# STM32N655 register map
File version: 1.0
CPU: CM55 r0p1, little endian, no MPU, FPU, vendor SysTick, 8 interrupt priority bits
Registers are 32-bit, read-write, reset 0x0 unless marked. A register's access mark holds for its fields unless they carry their own. Offsets are from the block's base; [hi:lo] are bit positions; 'fields as' and 'values as' point back to an identical list.

## LTDC — LCD-TFT display controller
Base 0x48001000
Same registers: LTDC_S 0x58001000
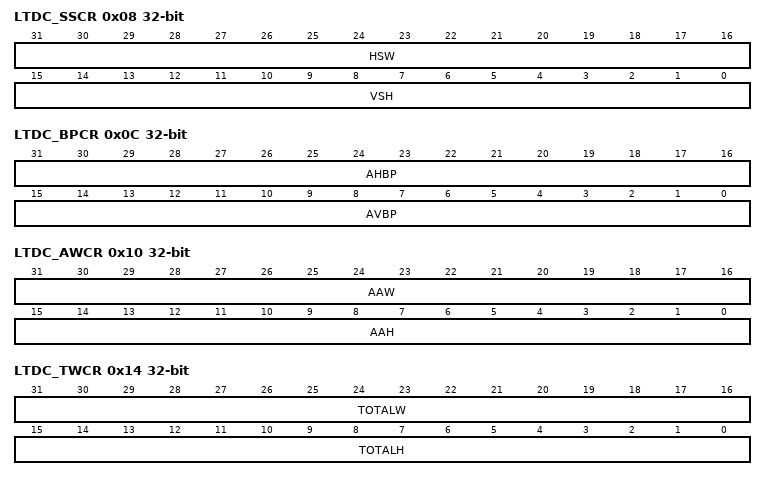
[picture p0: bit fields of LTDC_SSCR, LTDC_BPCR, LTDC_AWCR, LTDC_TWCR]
0x08 LTDC_SSCR — LTDC synchronization size configuration register
  [31:16] HSW — horizontal synchronization width (in units of pixel clock period)
  [15:0] VSH — vertical synchronization height (in units of horizontal scan line)
0x0C LTDC_BPCR — LTDC back porch configuration register
  [31:16] AHBP — accumulated horizontal back porch (in units of pixel clock period)
  [15:0] AVBP — accumulated Vertical back porch (in units of horizontal scan line)
0x10 LTDC_AWCR — LTDC active width configuration register
  [31:16] AAW — accumulated active width (in units of pixel clock period)
  [15:0] AAH — accumulated active height (in units of horizontal scan line)
0x14 LTDC_TWCR — LTDC total width configuration register
  [31:16] TOTALW — total width (in units of pixel clock period)
  [15:0] TOTALH — total height (in units of horizontal scan line)
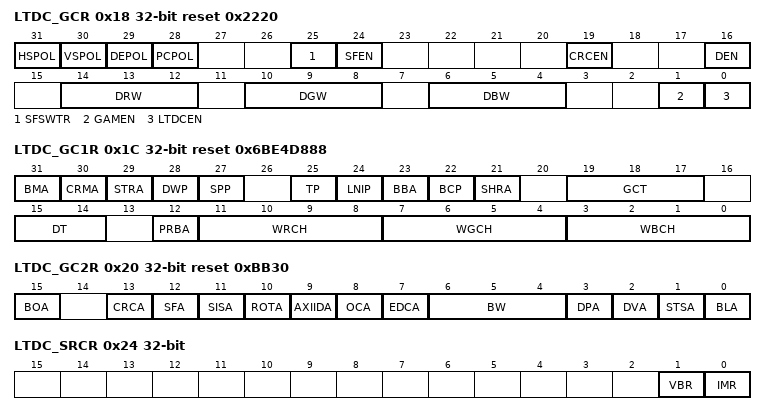
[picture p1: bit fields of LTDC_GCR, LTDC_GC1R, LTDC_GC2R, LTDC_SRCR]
0x18 LTDC_GCR access per field reset 0x2220 — LTDC global control register
  [31] HSPOL rw — horizontal synchronization polarity
    0=horizontal synchronization polarity is active low; 1=horizontal synchronization polarity is active high
  [30] VSPOL rw — vertical synchronization polarity
    0=vertical synchronization is active low; 1=vertical synchronization is active high
  [29] DEPOL rw — blanking (no data/pixel) polarity
    0=blanking (no data/pixel) polarity is active low; 1=blanking (no data/pixel) polarity is active high
  [28] PCPOL rw — pixel clock polarity
    0=the pixel and sync data are generated at the rising-edge of the output LCD_CLK clock; 1=the pixel and sync data are generated at the falling-edge of the output LCD_CLK clock
  [25] SFSWTR wo — single-frame mode: software trigger
    0=no action; 1=triggers one frame
  [24] SFEN rw — single-frame mode: mode enable
    0=single-frame disabled: a trigger (on SFSWTR) generates a continuous flow; 1=single-frame enabled: a trigger (on SFSWTR) generates a single frame
  [19] CRCEN rw — CRC enable
    0=CRC disabled; 1=CRC enabled
  [16] DEN rw — dither enable
    0=dither disabled; 1=dither enabled
  [14:12] DRW ro — dither red width
  [10:8] DGW ro — dither green width
  [6:4] DBW ro — dither blue width
  [1] GAMEN rw — Gamma correction enable
    0=Gamma correction disabled (pixels bypass the gamma operator); 1=Gamma correction enabled
  [0] LTDCEN rw — LTDC global enable
    0=LTDC disabled; 1=LTDC enabled
0x1C LTDC_GC1R ro reset 0x6BE4D888 — LTDC global configuration 1 register
  [31] BMA — blind mode ability
  [30] CRMA — configuration reading mode ability
  [29] STRA — status register ability
  [28] DWP — dither width programmability
  [27] SPP — sync polarity programmability
  [25] TP — timing programmability
  [24] LNIP — line-IRQ: line position programmability
  [23] BBA — background blending ability
  [22] BCP — background color programmability (unique color blended as background)
  [21] SHRA — shadow registers ability
  [19:17] GCT — gamma correction technique implemented
    0=no gamma; 1=gamma with 256 samples; 2=gamma with 8 interpolated segments
  [15:14] DT — dithering technique implemented
    0=no dithering; 1=ordered 4x4 Bayer; 3=pseudo-random LFSR
  [12] PRBA — precise blending ability
  [11:8] WRCH — width of red channel output
  [7:4] WGCH — width of green channel output
  [3:0] WBCH — width of blue channel output
0x20 LTDC_GC2R ro reset 0xBB30 — LTDC global configuration 2 register
  [15] BOA — blending order ability
    0=blending order fixed; 1=blending order configurable
  [13] CRCA — CRC ability
    0=CRC no computation available; 1=CRC computation available
  [12] SFA — single frame mode ability
    0=single frame not available; 1=single frame available
  [11] SISA — second interrupt set ability
    0=second interrupt set not available; 1=second interrupt set available
  [10] ROTA — rotation support ability
  [9] AXIIDA — AXIID ability
  [8] OCA — output conversion ability (RGB to YCbCr)
  [7] EDCA — external display control ability
  [6:4] BW — bus width (log2 of number of bytes)
    2=32-bit bus; 3=64-bit bus; 4=128-bit bus
  [3] DPA — secondary RGB output port ability
  [2] DVA — dual-view ability
  [1] STSA — slave timings synchronization ability
  [0] BLA — background layer ability (pixels of background layer are read from memory)
0x24 LTDC_SRCR — LTDC shadow reload configuration register
  [1] VBR — vertical blanking reload request
    0=no effect; 1=The shadow registers are reloaded during the vertical blanking period (at the beginning of the first line after the active display area)
  [0] IMR — immediate reload trigger
    0=no effect; 1=The shadow registers are reloaded immediately
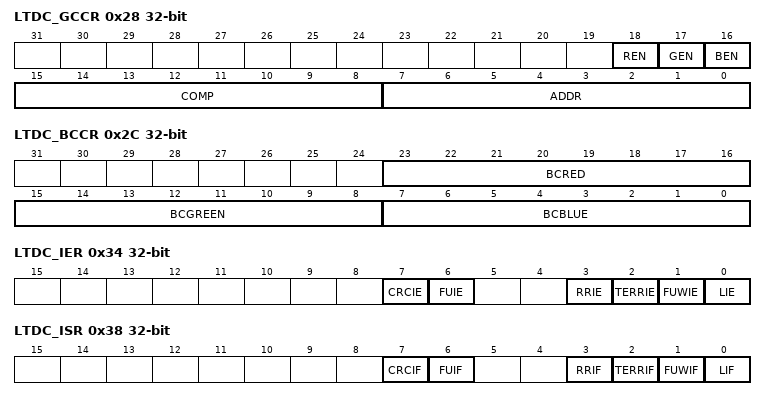
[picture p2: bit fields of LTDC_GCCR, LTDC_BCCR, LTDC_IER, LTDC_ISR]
0x28 LTDC_GCCR wo — LTDC gamma correction configuration register
  [18] REN — write trigger to the red table
    0=no action done; 1=COMP is written at ADDR in the red table
  [17] GEN — write trigger to the green table
    0=no action done; 1=COMP is written at ADDR in the green table
  [16] BEN — write trigger to the blue table
    0=no action done; 1=COMP is written at ADDR in the blue table
  [15:8] COMP — color component to be written, in either (or all) the R,G,B tables
  [7:0] ADDR — address of the R,G,B table where the COMP component is written
0x2C LTDC_BCCR — LTDC background color configuration register
  [23:16] BCRED — background color red value
  [15:8] BCGREEN — background color green value
  [7:0] BCBLUE — background color blue value
0x34 LTDC_IER — LTDC interrupt enable register
  [7] CRCIE — CRC error interrupt enable
    0=CRC error disabled; 1=CRC error interrupt enabled
  [6] FUIE — FIFO underrun interrupt enable
    0=FIFO underrun interrupt disabled; 1=FIFO underrun Interrupt enabled
  [3] RRIE — Register reload interrupt enable
    0=register reload interrupt disabled; 1=register reload interrupt enabled
  [2] TERRIE — Transfer Error interrupt enable
    0=transfer error interrupt disabled; 1=transfer error interrupt enabled
  [1] FUWIE — FIFO underrun warning interrupt enable
    values as FUIE
  [0] LIE — Line interrupt enable
    0=line interrupt disabled; 1=line interrupt enabled
0x38 LTDC_ISR ro — LTDC interrupt status register
  [7] CRCIF — CRC error interrupt flag
    0=no CRC error interrupt generated; 1=CRC error interrupt generated when a bus error occurs
  [6] FUIF — FIFO underrun interrupt flag
    0=no FIFO underrun interrupt generated; 1=FIFO underrun interrupt generated, if one of the layer FIFOs is empty and many pixel data are read from the FIFO
  [3] RRIF — Register reload interrupt flag
    0=no register reload interrupt generated; 1=register reload interrupt generated when a vertical blanking reload occurs (and the first line after the active area is reached)
  [2] TERRIF — Transfer error interrupt flag
    0=no transfer error interrupt generated; 1=transfer error interrupt generated when a bus error occurs
  [1] FUWIF — FIFO underrun warning interrupt flag
    0=no FIFO underrun warning interrupt generated; 1=FIFO underrun warning interrupt generated, if one of the layer FIFO is empty and pixel data is read from the FIFO
  [0] LIF — Line interrupt flag
    0=no line interrupt generated; 1=line interrupt generated when a programmed line is reached
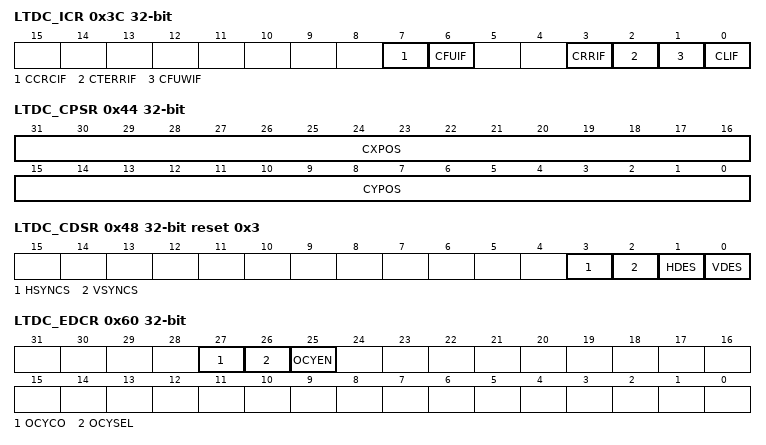
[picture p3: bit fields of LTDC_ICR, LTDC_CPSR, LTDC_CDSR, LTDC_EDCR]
0x3C LTDC_ICR wo — LTDC interrupt clear register
  [7] CCRCIF — clears the CRC error interrupt flag
    0=no effect; 1=clears the CRCIF flag in LTDC_ISR
  [6] CFUIF — clears the FIFO underrun interrupt flag
    0=no effect; 1=clears the FUIF flag in LTDC_ISR
  [3] CRRIF — clears register reload interrupt flag
    0=no effect; 1=clears the RRIF flag in LTDC_ISR
  [2] CTERRIF — clears the transfer error interrupt flag
    0=no effect; 1=clears the TERRIF flag in LTDC_ISR
  [1] CFUWIF — clears the FIFO underrun warning interrupt flag
    0=no effect; 1=clears the FUWIF flag in LTDC_ISR
  [0] CLIF — clears the line interrupt flag
    0=no effect; 1=clears the LIF flag in LTDC_ISR
0x40 LTDC_LIPCR — LTDC line interrupt position configuration register
  [15:0] LIPOS — line interrupt position
0x44 LTDC_CPSR ro — LTDC current position status register
  [31:16] CXPOS — current X position
  [15:0] CYPOS — current Y position
0x48 LTDC_CDSR ro reset 0x3 — LTDC current display status register
  [all] fields
    0=active low; 1=active high
  [3] HSYNCS — horizontal synchronization display status
  [2] VSYNCS — vertical synchronization display status
  [1] HDES — horizontal data enable display status
  [0] VDES — vertical data enable display status
0x60 LTDC_EDCR — LTDC external display control register
  [27] OCYCO — output conversion to YCbCr 422
    0=Cb is output first (Y0Cb, then Y1Cr, Y2Cb and so on); 1=Cr is output first (Y0Cr, then Y1Cb, Y2Cr and so on)
  [26] OCYSEL — output conversion to YCbCr 422
    0=use ITU-R BT.601 set (for typically SDTV analog-like displays); 1=use ITU-R BT.709 set (for typically HDTV digital-like displays)
  [25] OCYEN — output conversion to YCbCr 422 enable
    0=conversion disabled; 1=conversion enabled
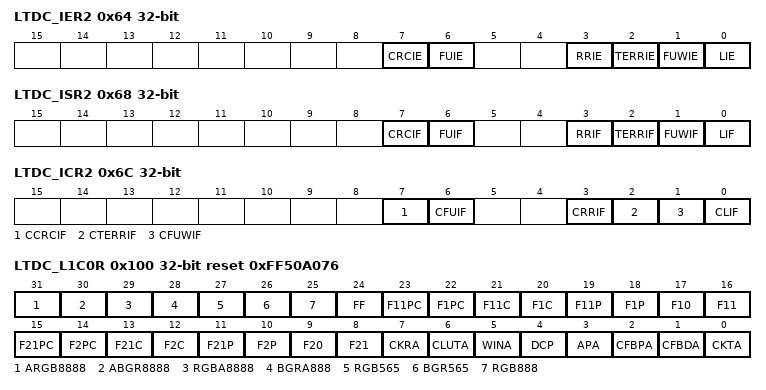
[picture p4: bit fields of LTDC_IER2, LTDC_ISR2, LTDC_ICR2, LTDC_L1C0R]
0x64 LTDC_IER2 — LTDC interrupt enable register 2
  [7] CRCIE — CRC error interrupt enable
    0=CRC error disabled; 1=CRC error interrupt enabled
  [6] FUIE — FIFO underrun interrupt enable
    values as LTDC_IER.FUIE
  [3] RRIE — Register reload interrupt enable
    values as LTDC_IER.RRIE
  [2] TERRIE — Transfer error interrupt enable
    values as LTDC_IER.TERRIE
  [1] FUWIE — FIFO underrun warning interrupt enable
    values as LTDC_IER.FUIE
  [0] LIE — Line interrupt enable
    0=line interrupt disabled; 1=line interrupt enabled
0x68 LTDC_ISR2 ro — LTDC interrupt status register 2
  [7] CRCIF — CRC Error interrupt flag
    values as LTDC_ISR.CRCIF
  [6] FUIF — FIFO underrun interrupt flag
    0=no FIFO underrun interrupt generated; 1=FIFO underrun interrupt generated, if one of the layer FIFO is empty and many pixel data are read from the FIFO
  [3] RRIF — Register reload interrupt flag
    values as LTDC_ISR.RRIF
  [2] TERRIF — Transfer error interrupt flag
    values as LTDC_ISR.TERRIF
  [1] FUWIF — FIFO underrun warning interrupt flag
    values as LTDC_ISR.FUWIF
  [0] LIF — Line interrupt flag
    values as LTDC_ISR.LIF
0x6C LTDC_ICR2 wo — LTDC interrupt clear register 2
  [7] CCRCIF — clears the CRC error interrupt flag
    0=no effect; 1=clears the CRCIF flag in LTDC_ISR2
  [6] CFUIF — clears the FIFO underrun interrupt flag
    0=no effect; 1=clears the FUIF flag in LTDC_ISR2
  [3] CRRIF — clears register reload interrupt flag
    0=no effect; 1=clears the RRIF flag in LTDC_ISR2
  [2] CTERRIF — clears the Transfer Error interrupt flag
    0=no effect; 1=clears the TERRIF flag in LTDC_ISR2
  [1] CFUWIF — clears the FIFO underrun warning interrupt flag
    0=no effect; 1=clears the FUWIF flag in LTDC_ISR2
  [0] CLIF — clears the Line interrupt flag
    0=no effect; 1=clears the LIF flag in LTDC_ISR2
0x70 LTDC_LIPCR2 — LTDC line interrupt position configuration register 2
  [15:0] LIPOS — line interrupt position
0x78 LTDC_ECRCR — LTDC expected CRC register
  [15:0] ECRC — expected CRC of frame
0x7C LTDC_CCRCR ro — LTDC computed CRC register
  [15:0] CCRC — computed CRC of frame
0x90 LTDC_FUTR reset 0x10 — LTDC FIFO underrun threshold register
  [15:0] THRE — threshold to trigger a FIFO underrun interrupt (per FIFO word, 64 bits)
0x100 LTDC_L1C0R ro reset 0xFF50A076 — LTDC layerx configuration 0 register
  [31] ARGB8888 — pixel format, ability for argb8888
  [30] ABGR8888 — pixel format, ability for abgr8888
  [29] RGBA8888 — pixel format, ability for rgba8888
  [28] BGRA888 — pixel format, ability for bgra8888
  [27] RGB565 — pixel format, ability for rgb565
  [26] BGR565 — pixel format, ability for bgr565
  [25] RGB888 — pixel format, ability for rgb888
  [24] FF — flexible pixel format, ability
  [23] F11PC — blending factor 1, ability for: 1.0 - (pixel_alpha * constant_alpha)
  [22] F1PC — blending factor 1, ability for: pixel_alpha * constant_alpha
  [21] F11C — blending factor 1, ability for: 1.0 - constant_alpha
  [20] F1C — blending factor 1, ability for: constant_alpha
  [19] F11P — blending factor 1, ability for: 1.0 - pixel_alpha
  [18] F1P — blending factor 1, ability for: pixel_alpha
  [17] F10 — blending factor 1,ability for: 0.0
  [16] F11 — blending factor 1, ability for: 1.0
  [15] F21PC — blending factor 2, ability for: 1.0 - (pixel_alpha * constant_alpha)
  [14] F2PC — blending factor 2, ability for: pixel_alpha * constant_alpha
  [13] F21C — blending factor 2, ability for: 1.0 - constant_alpha
  [12] F2C — blending factor 2, ability for: constant_alpha
  [11] F21P — blending factor 2, ability for: 1.0 - pixel_alpha
  [10] F2P — blending factor 2, ability for: pixel_alpha
  [9] F20 — blending factor 2, ability for: 0.0
  [8] F21 — blending factor 2, ability for: 1.0
  [7] CKRA — color key replace ability
  [6] CLUTA — CLUT ability
  [5] WINA — windowing ability
  [4] DCP — default color programmability
  [3] APA — alpha plane ability
  [2] CFBPA — color frame buffer pitch ability
  [1] CFBDA — color frame buffer duplication ability
  [0] CKTA — color key transparency ability
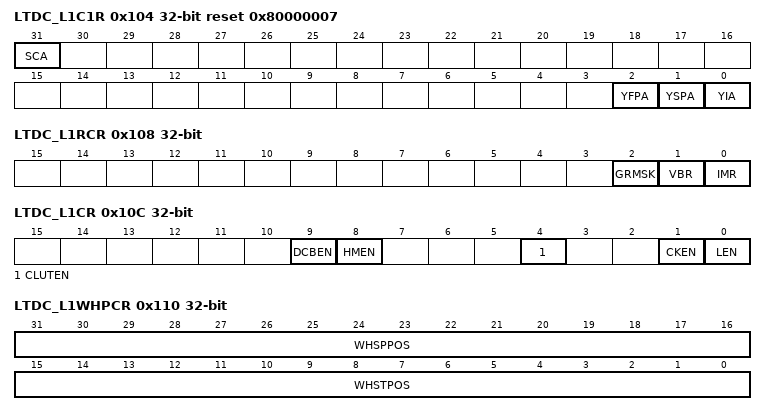
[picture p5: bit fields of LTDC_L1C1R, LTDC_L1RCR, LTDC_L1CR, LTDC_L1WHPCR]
0x104 LTDC_L1C1R access per field reset 0x80000007 — LTDC layerx configuration 1 register
  [31] SCA rw — scaling ability for that layer
    0=scaling not available; 1=scaling available
  [2] YFPA rw — YCbCr 420 full-planar ability for that layer
    0=full planar not available; 1=full planar available
  [1] YSPA rw — YCbCr 420 semi-planar ability for that layer
    0=semi-planar not available; 1=semi-planar available
  [0] YIA wo — YCbCr 422 interleaved ability for that layer
    0=interleaved not available; 1=interleaved available
0x108 LTDC_L1RCR access per field — LTDC layerx reload control register
  [2] GRMSK rw — shadow reload control, global (centralized) reload masked
    0=global reload active for this layer (control from LTDC_SRCR enabled); 1=global reload masked for this layer (control from LTDC_SRCR disabled)
  [1] VBR rw — vertical blanking reload request
    values as LTDC_SRCR.VBR
  [0] IMR wo — immediate reload trigger
    0=no effect; 1=The shadow registers are reloaded immediately
0x10C LTDC_L1CR — LTDC layerx control register
  [9] DCBEN — default color blending enable
    0=blending disabled; 1=blending enabled
  [8] HMEN — horizontal mirroring enable
    0=mirror disabled; 1=mirror enabled (if so, the color frame buffer start address has to be set to the last byte of the first line, so for instance: if line is 100 pixels, 24 bpp, then address is set to 299)
  [4] CLUTEN — color look-up table enable
    0=color look-up table disabled; 1=color look-up table enabled
  [1] CKEN — color keying enable
    0=color keying disabled; 1=color keying enabled: if RGB matches, then the ARGB are set to 0
  [0] LEN — layer enable
    0=layer disabled; 1=layer enabled
0x110 LTDC_L1WHPCR — LTDC layerx window horizontal position configuration register
  [31:16] WHSPPOS — window horizontal stop position
  [15:0] WHSTPOS — window horizontal start position
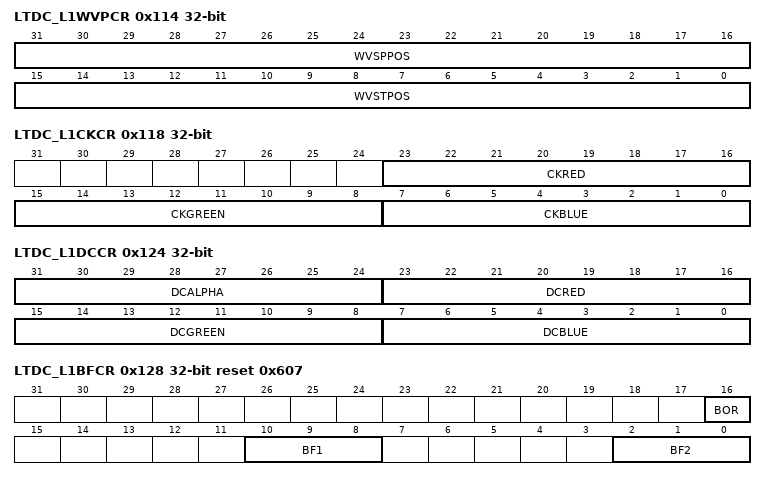
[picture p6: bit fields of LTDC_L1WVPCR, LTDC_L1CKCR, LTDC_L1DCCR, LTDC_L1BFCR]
0x114 LTDC_L1WVPCR — LTDC layerx window vertical position configuration register
  [31:16] WVSPPOS — window vertical stop position
  [15:0] WVSTPOS — window vertical start position
0x118 LTDC_L1CKCR — LTDC layerx color keying configuration register
  [23:16] CKRED — color key red value
  [15:8] CKGREEN — color key green value
  [7:0] CKBLUE — color key blue value
0x11C LTDC_L1PFCR — LTDC layerx pixel format configuration register
  [2:0] PF — pixel format
    0=ARGB8888 (32 bpp); 1=ABGR888 (32 bpp); 2=RGBA888 (32 bpp); 3=BGRA8888 (32 bpp); 4=RGB565 (16 bpp, A = 255); 5=BGR565 (16 bpp, A = 255); 6=RGB888 (24 bpp packed, A = 255); 7=Flexible pixel format selected (see Section 38.7.50 and Section 38.7.51)
0x120 LTDC_L1CACR reset 0xFF — LTDC layerx constant alpha configuration register
  [7:0] CONSTA — constant alpha
0x124 LTDC_L1DCCR — LTDC layerx default color configuration register
  [31:24] DCALPHA — default color alpha
  [23:16] DCRED — default color red
  [15:8] DCGREEN — default color green
  [7:0] DCBLUE — default color blue
0x128 LTDC_L1BFCR reset 0x607 — LTDC layerx blending factors configuration register
  [16] BOR — blending order
    0=layer set in background; 1=layer set in foreground
  [10:8] BF1 — blending factor 1
    4=constant alpha; 6=pixel alpha x constant alpha
  [2:0] BF2 — blending factor 2
    5=1 - constant alpha; 7=1 - (pixel alpha x constant alpha)
0x12C LTDC_L1BLCR — LTDC layerx burst length configuration register
  [7:0] BL — burst length
    0=maximum burst length (16 words 64 bits, thus 128 Bytes); 1=1 word (of 64 bits) per burst; 16=16 words (of 64 bits) per burst
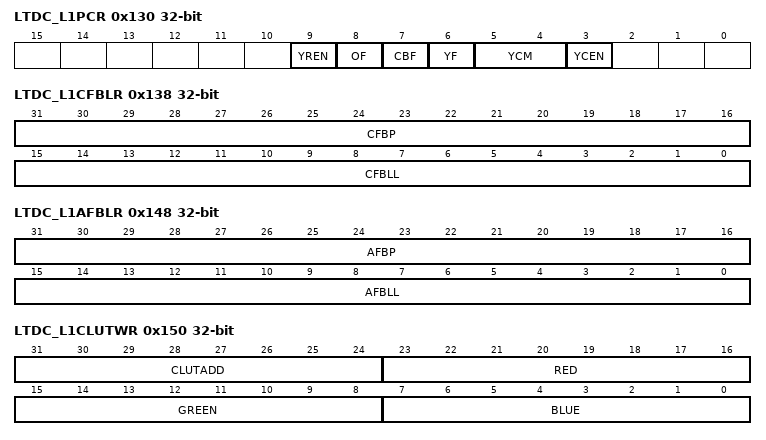
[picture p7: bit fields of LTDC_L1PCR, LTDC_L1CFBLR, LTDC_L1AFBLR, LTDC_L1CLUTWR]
0x130 LTDC_L1PCR — LTDC layerx planar configuration register
  [9] YREN — Y rescale enable for the color dynamic range
    0=rescaling disabled (input component thus assumed provided in 0 to 255); 1=rescaling enabled (input component thus assumed provided in 16 to 235)
  [8] OF — Odd pixel first
    0=odd pixel disabled (thus even pixel on byte 0); 1=odd pixel enabled (thus odd pixel on byte 0)
  [7] CBF — Cb component first
    0=Cb disabled (thus Cr component is on byte 0 and 1); 1=Cb enabled (thus Cb component is on byte 0 and 1)
  [6] YF — Y component first
    0=Y component disabled (thus Cr or Cb component is on byte 0); 1=Y component enabled (thus Y component is on byte 0)
  [5:4] YCM — YCbCr conversion mode
    0=interleaved 422 (Cb and Cr component are replicated horizontally for pixels P and P+1); 1=semi-Planar 420: (Cb and Cr component are replicated horizontally and vertically.The layer main configuration defines the access to the Y buffer, and auxiliary registers define the access to the Cb and Cr buffers); 2=full-Planar 420: (Cb and Cr component are replicated horizontally and vertically. The layer main configuration defines the access to the Y buffer, and auxiliary registers define the access to the Cb and Cr buffers).
  [3] YCEN — YCbCr-to-RGB conversion enable
    0=conversion disabled; 1=YCbCr conversion enabled, using the YCM setting above
0x134 LTDC_L1CFBAR — LTDC layerx color frame buffer address register
  [31:0] CFBADD — color frame buffer start address
0x138 LTDC_L1CFBLR — LTDC layerx color frame buffer length register
  [31:16] CFBP — color frame buffer pitch in bytes
  [15:0] CFBLL — color frame buffer line length
0x13C LTDC_L1CFBLNR — LTDC layerx color frame buffer line number register
  [15:0] CFBLNBR — frame buffer line number
0x140 LTDC_L1AFBA0R — LTDC layer1 auxiliary frame buffer address 0 register
  [31:0] AFBADD0 — frame buffer start address
0x144 LTDC_L1AFBA1R — LTDC layer1 auxiliary frame buffer address 1 register
  [31:0] AFBADD1 — auxiliary frame buffer start address
0x148 LTDC_L1AFBLR — LTDC layer1 auxiliary frame buffer length register
  [31:16] AFBP — auxiliary frame buffer pitch in bytes
  [15:0] AFBLL — auxiliary frame buffer line length
0x14C LTDC_L1AFBLNR — LTDC layer1 auxiliary frame buffer line number register
  [15:0] AFBLNBR — auxiliary frame buffer line number
0x150 LTDC_L1CLUTWR wo — LTDC layerx CLUT write register
  [31:24] CLUTADD — CLUT address
  [23:16] RED — red value
  [15:8] GREEN — green value
  [7:0] BLUE — blue value
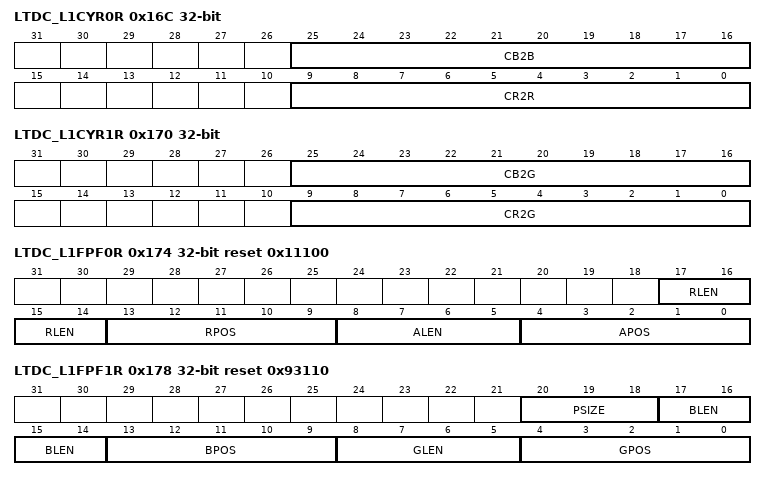
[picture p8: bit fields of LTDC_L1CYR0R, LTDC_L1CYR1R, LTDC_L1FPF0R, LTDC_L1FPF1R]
0x16C LTDC_L1CYR0R — LTDC layerx conversion YCbCr RGB 0 register
  [25:16] CB2B — Cb-to-Blue coefficient, with bits 9:8 as positive integer and 7:0 as decimals.
  [9:0] CR2R — Cr-to-Red coefficient, with bits 9:8 as positive integer and 7:0 as decimals.
0x170 LTDC_L1CYR1R — LTDC layerx conversion YCbCr RGB 1 register
  [25:16] CB2G — Cb-to-Green coefficient, with bits 9:8 as positive integer and 7:0 as decimals.
  [9:0] CR2G — Cr-to-Green coefficient, with bits 9:8 as positive integer and 7:0 as decimals.
0x174 LTDC_L1FPF0R reset 0x11100 — LTDC layerx flexible pixel format 0 register
  [17:14] RLEN — Width of the Red component (in bits)
  [13:9] RPOS — Location of the Red component inside the pixel memory word (in bits)
  [8:5] ALEN — Width of the Alpha component (in bits)
  [4:0] APOS — Location of the Alpha component inside the pixel memory word (in bits)
0x178 LTDC_L1FPF1R reset 0x93110 — LTDC layerx flexible pixel format 1 register
  [20:18] PSIZE — Pixel size (in bytes)
  [17:14] BLEN — Width of the Blue component (in bits)
  [13:9] BPOS — Location of the Blue component inside the pixel memory word (in bits)
  [8:5] GLEN — Width of the Green component (in bits)
  [4:0] GPOS — Location of the Green component inside the pixel memory word (in bits)
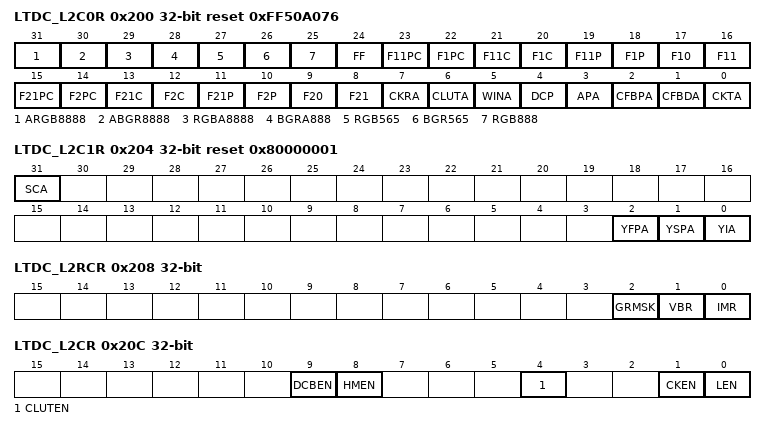
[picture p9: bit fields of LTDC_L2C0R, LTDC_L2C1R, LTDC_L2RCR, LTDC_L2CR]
0x200 LTDC_L2C0R ro reset 0xFF50A076 — LTDC layerx configuration 0 register
  fields as LTDC_L1C0R
0x204 LTDC_L2C1R access per field reset 0x80000001 — LTDC layerx configuration 1 register
  fields as LTDC_L1C1R
0x208 LTDC_L2RCR access per field — LTDC layerx reload control register
  fields as LTDC_L1RCR
0x20C LTDC_L2CR — LTDC layerx control register
  fields as LTDC_L1CR
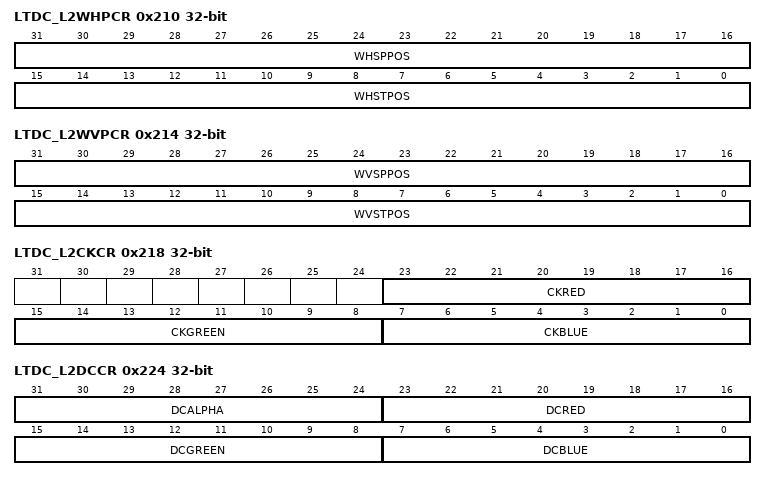
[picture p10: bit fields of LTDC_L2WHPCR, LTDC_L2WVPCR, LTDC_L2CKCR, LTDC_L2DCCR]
0x210 LTDC_L2WHPCR — LTDC layerx window horizontal position configuration register
  fields as LTDC_L1WHPCR
0x214 LTDC_L2WVPCR — LTDC layerx window vertical position configuration register
  fields as LTDC_L1WVPCR
0x218 LTDC_L2CKCR — LTDC layerx color keying configuration register
  fields as LTDC_L1CKCR
0x21C LTDC_L2PFCR — LTDC layerx pixel format configuration register
  fields as LTDC_L1PFCR
0x220 LTDC_L2CACR reset 0xFF — LTDC layerx constant alpha configuration register
  [7:0] CONSTA — constant alpha
0x224 LTDC_L2DCCR — LTDC layerx default color configuration register
  fields as LTDC_L1DCCR
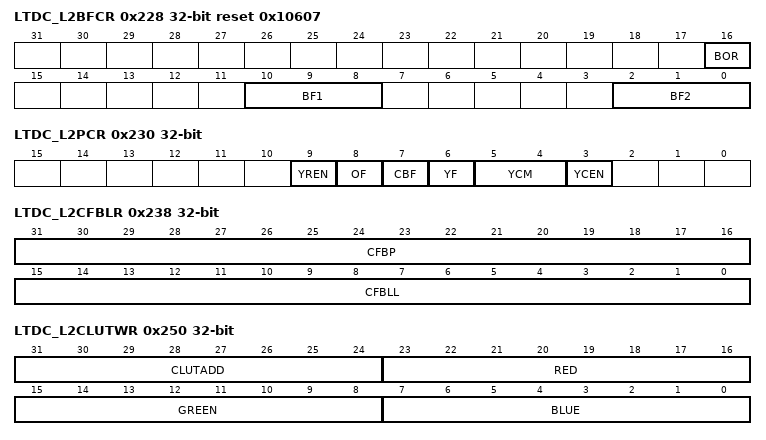
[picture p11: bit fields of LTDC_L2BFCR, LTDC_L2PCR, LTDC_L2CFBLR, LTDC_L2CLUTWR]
0x228 LTDC_L2BFCR reset 0x10607 — LTDC layerx blending factors configuration register
  fields as LTDC_L1BFCR
0x22C LTDC_L2BLCR — LTDC layerx burst length configuration register
  fields as LTDC_L1BLCR
0x230 LTDC_L2PCR — LTDC layerx planar configuration register
  fields as LTDC_L1PCR
0x234 LTDC_L2CFBAR — LTDC layerx color frame buffer address register
  [31:0] CFBADD — color frame buffer start address
0x238 LTDC_L2CFBLR — LTDC layerx color frame buffer length register
  fields as LTDC_L1CFBLR
0x23C LTDC_L2CFBLNR — LTDC layerx color frame buffer line number register
  [15:0] CFBLNBR — frame buffer line number
0x250 LTDC_L2CLUTWR wo — LTDC layerx CLUT write register
  fields as LTDC_L1CLUTWR
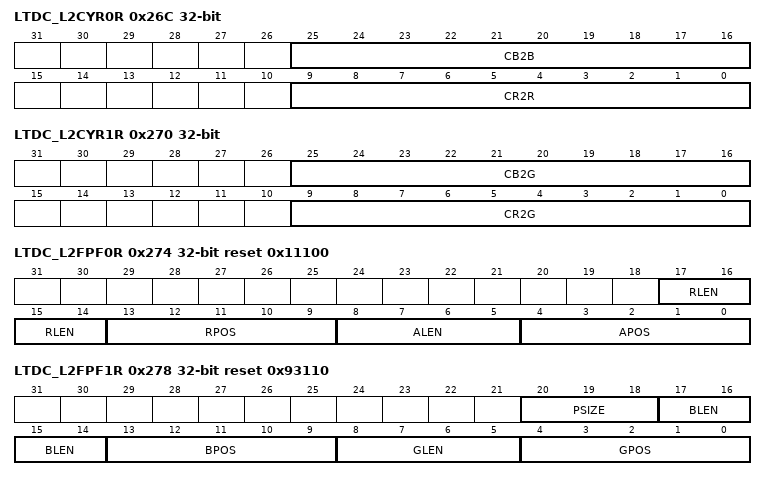
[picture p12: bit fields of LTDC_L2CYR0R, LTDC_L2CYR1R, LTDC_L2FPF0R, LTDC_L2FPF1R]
0x26C LTDC_L2CYR0R — LTDC layerx conversion YCbCr RGB 0 register
  fields as LTDC_L1CYR0R
0x270 LTDC_L2CYR1R — LTDC layerx conversion YCbCr RGB 1 register
  fields as LTDC_L1CYR1R
0x274 LTDC_L2FPF0R reset 0x11100 — LTDC layerx flexible pixel format 0 register
  fields as LTDC_L1FPF0R
0x278 LTDC_L2FPF1R reset 0x93110 — LTDC layerx flexible pixel format 1 register
  fields as LTDC_L1FPF1R
